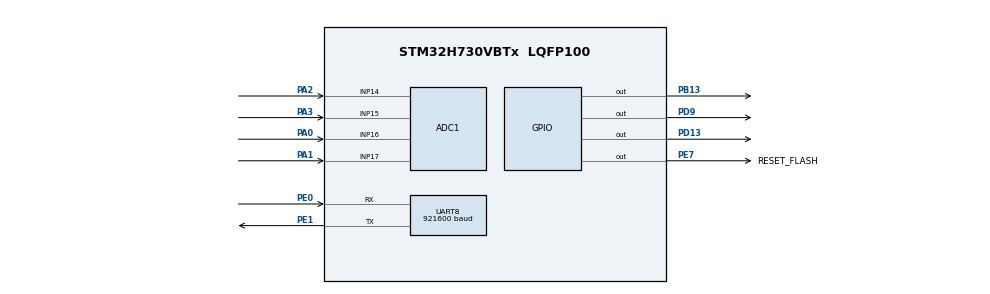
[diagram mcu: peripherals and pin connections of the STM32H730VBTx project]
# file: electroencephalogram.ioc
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ADC1.Channel-6\#ChannelRegularConversion=ADC_CHANNEL_14
ADC1.Channel-7\#ChannelRegularConversion=ADC_CHANNEL_15
ADC1.Channel-8\#ChannelRegularConversion=ADC_CHANNEL_16
ADC1.Channel-9\#ChannelRegularConversion=ADC_CHANNEL_17
ADC1.ClockPrescaler=ADC_CLOCK_ASYNC_DIV1
ADC1.ContinuousConvMode=ENABLE
ADC1.ConversionDataManagement=ADC_CONVERSIONDATA_DMA_CIRCULAR
ADC1.ExternalTrigConv=ADC_SOFTWARE_START
ADC1.NbrOfConversion=4
ADC1.NbrOfConversionFlag=1
ADC1.OffsetNumber-6\#ChannelRegularConversion=ADC_OFFSET_NONE
ADC1.OffsetNumber-7\#ChannelRegularConversion=ADC_OFFSET_NONE
ADC1.OffsetNumber-8\#ChannelRegularConversion=ADC_OFFSET_NONE
ADC1.OffsetNumber-9\#ChannelRegularConversion=ADC_OFFSET_NONE
ADC1.OffsetSignedSaturation-6\#ChannelRegularConversion=DISABLE
ADC1.OffsetSignedSaturation-7\#ChannelRegularConversion=DISABLE
ADC1.OffsetSignedSaturation-8\#ChannelRegularConversion=DISABLE
ADC1.OffsetSignedSaturation-9\#ChannelRegularConversion=DISABLE
ADC1.OversamplingMode=DISABLE
ADC1.Rank-6\#ChannelRegularConversion=1
ADC1.Rank-7\#ChannelRegularConversion=2
ADC1.Rank-8\#ChannelRegularConversion=3
ADC1.Rank-9\#ChannelRegularConversion=4
ADC1.Ratio=64
ADC1.SamplingTime-6\#ChannelRegularConversion=ADC_SAMPLETIME_2CYCLES_5
ADC1.SamplingTime-7\#ChannelRegularConversion=ADC_SAMPLETIME_2CYCLES_5
ADC1.SamplingTime-8\#ChannelRegularConversion=ADC_SAMPLETIME_2CYCLES_5
ADC1.SamplingTime-9\#ChannelRegularConversion=ADC_SAMPLETIME_2CYCLES_5
ADC1.master=1
CORTEX_M7.default_mode_Activation=1
Dma.ADC1.0.Direction=DMA_PERIPH_TO_MEMORY
Dma.ADC1.0.EventEnable=DISABLE
Dma.ADC1.0.FIFOMode=DMA_FIFOMODE_DISABLE
Dma.ADC1.0.Instance=DMA1_Stream0
Dma.ADC1.0.MemDataAlignment=DMA_MDATAALIGN_HALFWORD
Dma.ADC1.0.MemInc=DMA_MINC_ENABLE
Dma.ADC1.0.Mode=DMA_CIRCULAR
Dma.ADC1.0.PeriphDataAlignment=DMA_PDATAALIGN_HALFWORD
Dma.ADC1.0.PeriphInc=DMA_PINC_DISABLE
Dma.ADC1.0.Polarity=HAL_DMAMUX_REQ_GEN_RISING
Dma.ADC1.0.Priority=DMA_PRIORITY_LOW
Dma.ADC1.0.RequestNumber=1
Dma.ADC1.0.SignalID=NONE
Dma.ADC1.0.SyncEnable=DISABLE
Dma.ADC1.0.SyncPolarity=HAL_DMAMUX_SYNC_NO_EVENT
Dma.ADC1.0.SyncRequestNumber=1
Dma.ADC1.0.SyncSignalID=NONE
Dma.Request0=ADC1
Dma.Request1=UART8_TX
Dma.UART8_TX.1.Direction=DMA_MEMORY_TO_PERIPH
Dma.UART8_TX.1.EventEnable=DISABLE
Dma.UART8_TX.1.FIFOMode=DMA_FIFOMODE_DISABLE
Dma.UART8_TX.1.Instance=DMA1_Stream1
Dma.UART8_TX.1.MemDataAlignment=DMA_MDATAALIGN_BYTE
Dma.UART8_TX.1.MemInc=DMA_MINC_ENABLE
Dma.UART8_TX.1.Mode=DMA_CIRCULAR
Dma.UART8_TX.1.PeriphDataAlignment=DMA_PDATAALIGN_BYTE
Dma.UART8_TX.1.PeriphInc=DMA_PINC_DISABLE
Dma.UART8_TX.1.Polarity=HAL_DMAMUX_REQ_GEN_RISING
Dma.UART8_TX.1.Priority=DMA_PRIORITY_LOW
Dma.UART8_TX.1.RequestNumber=1
Dma.UART8_TX.1.SignalID=NONE
Dma.UART8_TX.1.SyncEnable=DISABLE
Dma.UART8_TX.1.SyncPolarity=HAL_DMAMUX_SYNC_NO_EVENT
Dma.UART8_TX.1.SyncRequestNumber=1
Dma.UART8_TX.1.SyncSignalID=NONE
Mcu.Family=STM32H7
Mcu.Name=STM32H730VBTx
Mcu.Package=LQFP100
NVIC.DMA1_Stream0_IRQn=true\:0\:0\:false\:false\:true\:false\:true\:true
NVIC.DMA1_Stream1_IRQn=true\:0\:0\:false\:false\:true\:false\:true\:true
NVIC.PriorityGroup=NVIC_PRIORITYGROUP_4
NVIC.UART8_IRQn=true\:3\:0\:true\:false\:true\:true\:true\:true
PA0.Mode=IN16-Single-Ended
PA0.Signal=ADC1_INP16
PA1.Mode=IN17-Single-Ended
PA1.Signal=ADC1_INP17
PA13(JTMS/SWDIO).Mode=Trace_Asynchronous_SW
PA13(JTMS/SWDIO).Signal=DEBUG_JTMS-SWDIO
PA14(JTCK/SWCLK).Mode=Trace_Asynchronous_SW
PA14(JTCK/SWCLK).Signal=DEBUG_JTCK-SWCLK
PA2.Signal=ADCx_INP14
PA3.Signal=ADCx_INP15
PA6.Signal=OCTOSPIM_P1_IO3
PA7.Signal=OCTOSPIM_P1_IO2
PB1.Signal=OCTOSPIM_P1_IO0
PB13.Signal=GPIO_Output
PB2.Signal=OCTOSPIM_P1_CLK
PB3(JTDO/TRACESWO).Mode=Trace_Asynchronous_SW
PB3(JTDO/TRACESWO).Signal=DEBUG_JTDO-SWO
PD13.Signal=GPIO_Output
PD9.Signal=GPIO_Output
PE0.Mode=Asynchronous
PE0.Signal=UART8_RX
PE1.Mode=Asynchronous
PE1.Signal=UART8_TX
PE7.GPIO_Label=RESET_FLASH
PE7.Signal=GPIO_Output
PH0-OSC_IN.Mode=HSE-External-Oscillator
PH0-OSC_IN.Signal=RCC_OSC_IN
PH1-OSC_OUT.Mode=HSE-External-Oscillator
PH1-OSC_OUT.Signal=RCC_OSC_OUT
ProjectManager.HeapSize=0x200
ProjectManager.StackSize=0x400
ProjectManager.TargetToolchain=STM32CubeIDE
RCC.ADCFreq_Value=38400000
RCC.APB1Freq_Value=30000000
RCC.APB2Freq_Value=30000000
RCC.APB3Freq_Value=30000000
RCC.APB4Freq_Value=30000000
RCC.CortexFreq_Value=30000000
RCC.DIVM1=2
RCC.DIVM2=4
RCC.DIVN1=16
RCC.DIVN2=12
RCC.DIVP2=5
RCC.DIVQ1=5
RCC.HCLKFreq_Value=30000000
RCC.HSE_VALUE=30000000
RCC.PLL2FRACN=0
RCC.PLL2_VCO_SEL-AdvancedSettings=RCC_PLL2VCOWIDE
RCC.PLLFRACN=0
RCC.SYSCLKFreq_VALUE=30000000
RCC.SYSCLKSource=RCC_SYSCLKSOURCE_HSE
RCC.USBFreq_Value=102400000
SH.ADCx_INP14.0=ADC1_INP14,IN14-Single-Ended
SH.ADCx_INP15.0=ADC1_INP15,IN15-Single-Ended
TIM3.Period=250-1
TIM3.Prescaler=30-1
TIM3.TIM_MasterOutputTrigger=TIM_TRGO_UPDATE
UART8.BaudRate=921600
VP_MEMORYMAP_VS_MEMORYMAP.Mode=CurAppReg
VP_TIM3_VS_ClockSourceINT.Mode=Internal
board=custom

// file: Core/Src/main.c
/* USER CODE BEGIN Header */
/**
  ******************************************************************************
  * @file           : main.c
  * @brief          : Main program body
  ******************************************************************************
  * @attention
  *
  * Copyright (c) 2025 STMicroelectronics.
  * All rights reserved.
  *
  * This software is licensed under terms that can be found in the LICENSE file
  * in the root directory of this software component.
  * If no LICENSE file comes with this software, it is provided AS-IS.
  *
  ******************************************************************************
  */
/* USER CODE END Header */
#include "main.h"

/* USER CODE BEGIN Includes */
#include "main.h"
#include "app.h"

/* USER CODE END Includes */

ADC_HandleTypeDef hadc1;
DMA_HandleTypeDef hdma_adc1;

TIM_HandleTypeDef htim3;

void SystemClock_Config(void);
static void MPU_Config(void);
static void MX_GPIO_Init(void);
static void MX_DMA_Init(void);
static void MX_UART8_Init(void);
static void MX_ADC1_Init(void);
static void MX_TIM3_Init(void);

int main(void)
{

  /* MPU Configuration--------------------------------------------------------*/
  MPU_Config();

  /* MCU Configuration--------------------------------------------------------*/

  /* Reset of all peripherals, Initializes the Flash interface and the Systick. */
  HAL_Init();

  /* Configure the system clock */
  SystemClock_Config();

  /* Initialize all configured peripherals */
  MX_GPIO_Init();
  MX_DMA_Init();
  MX_UART8_Init();
  MX_ADC1_Init();
  MX_TIM3_Init();
  /* USER CODE BEGIN 2 */

  app_setup();

  /* USER CODE END 2 */

  /* Infinite loop */
  while (1)
  {

    /* USER CODE BEGIN 3 */
	  app_loop();
  }
  /* USER CODE END 3 */
}

void SystemClock_Config(void)
{
  RCC_OscInitTypeDef RCC_OscInitStruct = {0};
  RCC_ClkInitTypeDef RCC_ClkInitStruct = {0};

  /** Supply configuration update enable
  */
  HAL_PWREx_ConfigSupply(PWR_LDO_SUPPLY);

  /** Configure the main internal regulator output voltage
  */
  __HAL_PWR_VOLTAGESCALING_CONFIG(PWR_REGULATOR_VOLTAGE_SCALE3);

  while(!__HAL_PWR_GET_FLAG(PWR_FLAG_VOSRDY)) {}

  /** Macro to configure the PLL clock source
  */
  __HAL_RCC_PLL_PLLSOURCE_CONFIG(RCC_PLLSOURCE_HSI);

  /** Initializes the RCC Oscillators according to the specified parameters
  * in the RCC_OscInitTypeDef structure.
  */
  RCC_OscInitStruct.OscillatorType = RCC_OSCILLATORTYPE_HSI|RCC_OSCILLATORTYPE_HSE;
  RCC_OscInitStruct.HSEState = RCC_HSE_ON;
  RCC_OscInitStruct.HSIState = RCC_HSI_DIV1;
  RCC_OscInitStruct.HSICalibrationValue = 64;
  RCC_OscInitStruct.PLL.PLLState = RCC_PLL_NONE;
  if (HAL_RCC_OscConfig(&RCC_OscInitStruct) != HAL_OK)
  {
    Error_Handler();
  }

  /** Initializes the CPU, AHB and APB buses clocks
  */
  RCC_ClkInitStruct.ClockType = RCC_CLOCKTYPE_HCLK|RCC_CLOCKTYPE_SYSCLK
                              |RCC_CLOCKTYPE_PCLK1|RCC_CLOCKTYPE_PCLK2
                              |RCC_CLOCKTYPE_D3PCLK1|RCC_CLOCKTYPE_D1PCLK1;
  RCC_ClkInitStruct.SYSCLKSource = RCC_SYSCLKSOURCE_HSE;
  RCC_ClkInitStruct.SYSCLKDivider = RCC_SYSCLK_DIV1;
  RCC_ClkInitStruct.AHBCLKDivider = RCC_HCLK_DIV1;
  RCC_ClkInitStruct.APB3CLKDivider = RCC_APB3_DIV1;
  RCC_ClkInitStruct.APB1CLKDivider = RCC_APB1_DIV1;
  RCC_ClkInitStruct.APB2CLKDivider = RCC_APB2_DIV1;
  RCC_ClkInitStruct.APB4CLKDivider = RCC_APB4_DIV1;

  if (HAL_RCC_ClockConfig(&RCC_ClkInitStruct, FLASH_LATENCY_0) != HAL_OK)
  {
    Error_Handler();
  }
}

static void MX_ADC1_Init(void)
{

  ADC_MultiModeTypeDef multimode = {0};
  ADC_ChannelConfTypeDef sConfig = {0};

  /** Common config
  */
  hadc1.Instance = ADC1;
  hadc1.Init.ClockPrescaler = ADC_CLOCK_ASYNC_DIV1;
  hadc1.Init.Resolution = ADC_RESOLUTION_16B;
  hadc1.Init.ScanConvMode = ADC_SCAN_ENABLE;
  hadc1.Init.EOCSelection = ADC_EOC_SINGLE_CONV;
  hadc1.Init.LowPowerAutoWait = DISABLE;
  hadc1.Init.ContinuousConvMode = ENABLE;
  hadc1.Init.NbrOfConversion = 4;
  hadc1.Init.DiscontinuousConvMode = DISABLE;
  hadc1.Init.ExternalTrigConv = ADC_SOFTWARE_START;
  hadc1.Init.ExternalTrigConvEdge = ADC_EXTERNALTRIGCONVEDGE_NONE;
  hadc1.Init.ConversionDataManagement = ADC_CONVERSIONDATA_DMA_CIRCULAR;
  hadc1.Init.Overrun = ADC_OVR_DATA_PRESERVED;
  hadc1.Init.LeftBitShift = ADC_LEFTBITSHIFT_NONE;
  hadc1.Init.OversamplingMode = DISABLE;
  hadc1.Init.Oversampling.Ratio = 64;
  if (HAL_ADC_Init(&hadc1) != HAL_OK)
  {
    Error_Handler();
  }

  /** Configure the ADC multi-mode
  */
  multimode.Mode = ADC_MODE_INDEPENDENT;
  if (HAL_ADCEx_MultiModeConfigChannel(&hadc1, &multimode) != HAL_OK)
  {
    Error_Handler();
  }

  /** Configure Regular Channel
  */
  sConfig.Channel = ADC_CHANNEL_14;
  sConfig.Rank = ADC_REGULAR_RANK_1;
  sConfig.SamplingTime = ADC_SAMPLETIME_2CYCLES_5;
  sConfig.SingleDiff = ADC_SINGLE_ENDED;
  sConfig.OffsetNumber = ADC_OFFSET_NONE;
  sConfig.Offset = 0;
  sConfig.OffsetSignedSaturation = DISABLE;
  if (HAL_ADC_ConfigChannel(&hadc1, &sConfig) != HAL_OK)
  {
    Error_Handler();
  }

  /** Configure Regular Channel
  */
  sConfig.Channel = ADC_CHANNEL_15;
  sConfig.Rank = ADC_REGULAR_RANK_2;
  if (HAL_ADC_ConfigChannel(&hadc1, &sConfig) != HAL_OK)
  {
    Error_Handler();
  }

  /** Configure Regular Channel
  */
  sConfig.Channel = ADC_CHANNEL_16;
  sConfig.Rank = ADC_REGULAR_RANK_3;
  if (HAL_ADC_ConfigChannel(&hadc1, &sConfig) != HAL_OK)
  {
    Error_Handler();
  }

  /** Configure Regular Channel
  */
  sConfig.Channel = ADC_CHANNEL_17;
  sConfig.Rank = ADC_REGULAR_RANK_4;
  if (HAL_ADC_ConfigChannel(&hadc1, &sConfig) != HAL_OK)
  {
    Error_Handler();
  }

}

static void MX_TIM3_Init(void)
{

  TIM_ClockConfigTypeDef sClockSourceConfig = {0};
  TIM_MasterConfigTypeDef sMasterConfig = {0};

  htim3.Instance = TIM3;
  htim3.Init.Prescaler = 30-1;
  htim3.Init.CounterMode = TIM_COUNTERMODE_UP;
  htim3.Init.Period = 250-1;
  htim3.Init.ClockDivision = TIM_CLOCKDIVISION_DIV1;
  htim3.Init.AutoReloadPreload = TIM_AUTORELOAD_PRELOAD_DISABLE;
  if (HAL_TIM_Base_Init(&htim3) != HAL_OK)
  {
    Error_Handler();
  }
  sClockSourceConfig.ClockSource = TIM_CLOCKSOURCE_INTERNAL;
  if (HAL_TIM_ConfigClockSource(&htim3, &sClockSourceConfig) != HAL_OK)
  {
    Error_Handler();
  }
  sMasterConfig.MasterOutputTrigger = TIM_TRGO_UPDATE;
  sMasterConfig.MasterSlaveMode = TIM_MASTERSLAVEMODE_DISABLE;
  if (HAL_TIMEx_MasterConfigSynchronization(&htim3, &sMasterConfig) != HAL_OK)
  {
    Error_Handler();
  }

}

static void MX_UART8_Init(void)
{

  LL_USART_InitTypeDef UART_InitStruct = {0};

  LL_GPIO_InitTypeDef GPIO_InitStruct = {0};
  RCC_PeriphCLKInitTypeDef PeriphClkInitStruct = {0};

  /** Initializes the peripherals clock
  */
  PeriphClkInitStruct.PeriphClockSelection = RCC_PERIPHCLK_UART8;
  PeriphClkInitStruct.Usart234578ClockSelection = RCC_USART234578CLKSOURCE_D2PCLK1;
  if (HAL_RCCEx_PeriphCLKConfig(&PeriphClkInitStruct) != HAL_OK)
  {
    Error_Handler();
  }

  /* Peripheral clock enable */
  LL_APB1_GRP1_EnableClock(LL_APB1_GRP1_PERIPH_UART8);

  LL_AHB4_GRP1_EnableClock(LL_AHB4_GRP1_PERIPH_GPIOE);
  /**UART8 GPIO Configuration
  PE0   ------> UART8_RX
  PE1   ------> UART8_TX
  */
  GPIO_InitStruct.Pin = LL_GPIO_PIN_0|LL_GPIO_PIN_1;
  GPIO_InitStruct.Mode = LL_GPIO_MODE_ALTERNATE;
  GPIO_InitStruct.Speed = LL_GPIO_SPEED_FREQ_LOW;
  GPIO_InitStruct.OutputType = LL_GPIO_OUTPUT_PUSHPULL;
  GPIO_InitStruct.Pull = LL_GPIO_PULL_NO;
  GPIO_InitStruct.Alternate = LL_GPIO_AF_8;
  LL_GPIO_Init(GPIOE, &GPIO_InitStruct);

  /* UART8 DMA Init */

  /* UART8_TX Init */
  LL_DMA_SetPeriphRequest(DMA1, LL_DMA_STREAM_1, LL_DMAMUX1_REQ_UART8_TX);

  LL_DMA_SetDataTransferDirection(DMA1, LL_DMA_STREAM_1, LL_DMA_DIRECTION_MEMORY_TO_PERIPH);

  LL_DMA_SetStreamPriorityLevel(DMA1, LL_DMA_STREAM_1, LL_DMA_PRIORITY_LOW);

  LL_DMA_SetMode(DMA1, LL_DMA_STREAM_1, LL_DMA_MODE_CIRCULAR);

  LL_DMA_SetPeriphIncMode(DMA1, LL_DMA_STREAM_1, LL_DMA_PERIPH_NOINCREMENT);

  LL_DMA_SetMemoryIncMode(DMA1, LL_DMA_STREAM_1, LL_DMA_MEMORY_INCREMENT);

  LL_DMA_SetPeriphSize(DMA1, LL_DMA_STREAM_1, LL_DMA_PDATAALIGN_BYTE);

  LL_DMA_SetMemorySize(DMA1, LL_DMA_STREAM_1, LL_DMA_MDATAALIGN_BYTE);

  LL_DMA_DisableFifoMode(DMA1, LL_DMA_STREAM_1);

  /* UART8 interrupt Init */
  NVIC_SetPriority(UART8_IRQn, NVIC_EncodePriority(NVIC_GetPriorityGrouping(),3, 0));
  NVIC_EnableIRQ(UART8_IRQn);

  UART_InitStruct.PrescalerValue = LL_USART_PRESCALER_DIV1;
  UART_InitStruct.BaudRate = 921600;
  UART_InitStruct.DataWidth = LL_USART_DATAWIDTH_8B;
  UART_InitStruct.StopBits = LL_USART_STOPBITS_1;
  UART_InitStruct.Parity = LL_USART_PARITY_NONE;
  UART_InitStruct.TransferDirection = LL_USART_DIRECTION_TX_RX;
  UART_InitStruct.HardwareFlowControl = LL_USART_HWCONTROL_NONE;
  UART_InitStruct.OverSampling = LL_USART_OVERSAMPLING_16;
  LL_USART_Init(UART8, &UART_InitStruct);
  LL_USART_DisableFIFO(UART8);
  LL_USART_SetTXFIFOThreshold(UART8, LL_USART_FIFOTHRESHOLD_1_8);
  LL_USART_SetRXFIFOThreshold(UART8, LL_USART_FIFOTHRESHOLD_1_8);
  LL_USART_ConfigAsyncMode(UART8);

  LL_USART_Enable(UART8);

  /* Polling UART8 initialisation */
  while((!(LL_USART_IsActiveFlag_TEACK(UART8))) || (!(LL_USART_IsActiveFlag_REACK(UART8))))
  {
  }

}

static void MX_DMA_Init(void)
{

  /* DMA controller clock enable */
  __HAL_RCC_DMA1_CLK_ENABLE();

  /* DMA interrupt init */
  /* DMA1_Stream0_IRQn interrupt configuration */
  HAL_NVIC_SetPriority(DMA1_Stream0_IRQn, 0, 0);
  HAL_NVIC_EnableIRQ(DMA1_Stream0_IRQn);
  /* DMA1_Stream1_IRQn interrupt configuration */
  NVIC_SetPriority(DMA1_Stream1_IRQn, NVIC_EncodePriority(NVIC_GetPriorityGrouping(),0, 0));
  NVIC_EnableIRQ(DMA1_Stream1_IRQn);

}

static void MX_GPIO_Init(void)
{
  GPIO_InitTypeDef GPIO_InitStruct = {0};

  /* GPIO Ports Clock Enable */
  __HAL_RCC_GPIOH_CLK_ENABLE();
  __HAL_RCC_GPIOA_CLK_ENABLE();
  __HAL_RCC_GPIOB_CLK_ENABLE();
  __HAL_RCC_GPIOE_CLK_ENABLE();
  __HAL_RCC_GPIOD_CLK_ENABLE();

  /*Configure GPIO pin Output Level */
  HAL_GPIO_WritePin(RESET_FLASH_GPIO_Port, RESET_FLASH_Pin, GPIO_PIN_RESET);

  /*Configure GPIO pin Output Level */
  HAL_GPIO_WritePin(GPIOB, GPIO_PIN_13, GPIO_PIN_RESET);

  /*Configure GPIO pin Output Level */
  HAL_GPIO_WritePin(GPIOD, GPIO_PIN_9|GPIO_PIN_13, GPIO_PIN_RESET);

  /*Configure GPIO pin : PA6 */
  GPIO_InitStruct.Pin = GPIO_PIN_6;
  GPIO_InitStruct.Mode = GPIO_MODE_AF_PP;
  GPIO_InitStruct.Pull = GPIO_NOPULL;
  GPIO_InitStruct.Speed = GPIO_SPEED_FREQ_VERY_HIGH;
  GPIO_InitStruct.Alternate = GPIO_AF6_OCTOSPIM_P1;
  HAL_GPIO_Init(GPIOA, &GPIO_InitStruct);

  /*Configure GPIO pin : PA7 */
  GPIO_InitStruct.Pin = GPIO_PIN_7;
  GPIO_InitStruct.Mode = GPIO_MODE_AF_PP;
  GPIO_InitStruct.Pull = GPIO_NOPULL;
  GPIO_InitStruct.Speed = GPIO_SPEED_FREQ_VERY_HIGH;
  GPIO_InitStruct.Alternate = GPIO_AF10_OCTOSPIM_P1;
  HAL_GPIO_Init(GPIOA, &GPIO_InitStruct);

  /*Configure GPIO pin : PB1 */
  GPIO_InitStruct.Pin = GPIO_PIN_1;
  GPIO_InitStruct.Mode = GPIO_MODE_AF_PP;
  GPIO_InitStruct.Pull = GPIO_NOPULL;
  GPIO_InitStruct.Speed = GPIO_SPEED_FREQ_VERY_HIGH;
  GPIO_InitStruct.Alternate = GPIO_AF4_OCTOSPIM_P1;
  HAL_GPIO_Init(GPIOB, &GPIO_InitStruct);

  /*Configure GPIO pin : PB2 */
  GPIO_InitStruct.Pin = GPIO_PIN_2;
  GPIO_InitStruct.Mode = GPIO_MODE_AF_PP;
  GPIO_InitStruct.Pull = GPIO_NOPULL;
  GPIO_InitStruct.Speed = GPIO_SPEED_FREQ_VERY_HIGH;
  GPIO_InitStruct.Alternate = GPIO_AF9_OCTOSPIM_P1;
  HAL_GPIO_Init(GPIOB, &GPIO_InitStruct);

  /*Configure GPIO pin : RESET_FLASH_Pin */
  GPIO_InitStruct.Pin = RESET_FLASH_Pin;
  GPIO_InitStruct.Mode = GPIO_MODE_OUTPUT_PP;
  GPIO_InitStruct.Pull = GPIO_NOPULL;
  GPIO_InitStruct.Speed = GPIO_SPEED_FREQ_LOW;
  HAL_GPIO_Init(RESET_FLASH_GPIO_Port, &GPIO_InitStruct);

  /*Configure GPIO pin : PB13 */
  GPIO_InitStruct.Pin = GPIO_PIN_13;
  GPIO_InitStruct.Mode = GPIO_MODE_OUTPUT_PP;
  GPIO_InitStruct.Pull = GPIO_NOPULL;
  GPIO_InitStruct.Speed = GPIO_SPEED_FREQ_LOW;
  HAL_GPIO_Init(GPIOB, &GPIO_InitStruct);

  /*Configure GPIO pins : PD9 PD13 */
  GPIO_InitStruct.Pin = GPIO_PIN_9|GPIO_PIN_13;
  GPIO_InitStruct.Mode = GPIO_MODE_OUTPUT_PP;
  GPIO_InitStruct.Pull = GPIO_NOPULL;
  GPIO_InitStruct.Speed = GPIO_SPEED_FREQ_LOW;
  HAL_GPIO_Init(GPIOD, &GPIO_InitStruct);

}

 /* MPU Configuration */

void MPU_Config(void)
{
  MPU_Region_InitTypeDef MPU_InitStruct = {0};

  /* Disables the MPU */
  HAL_MPU_Disable();

  /** Initializes and configures the Region and the memory to be protected
  */
  MPU_InitStruct.Enable = MPU_REGION_ENABLE;
  MPU_InitStruct.Number = MPU_REGION_NUMBER0;
  MPU_InitStruct.BaseAddress = 0x0;
  MPU_InitStruct.Size = MPU_REGION_SIZE_4GB;
  MPU_InitStruct.SubRegionDisable = 0x87;
  MPU_InitStruct.TypeExtField = MPU_TEX_LEVEL0;
  MPU_InitStruct.AccessPermission = MPU_REGION_NO_ACCESS;
  MPU_InitStruct.DisableExec = MPU_INSTRUCTION_ACCESS_DISABLE;
  MPU_InitStruct.IsShareable = MPU_ACCESS_SHAREABLE;
  MPU_InitStruct.IsCacheable = MPU_ACCESS_NOT_CACHEABLE;
  MPU_InitStruct.IsBufferable = MPU_ACCESS_NOT_BUFFERABLE;

  HAL_MPU_ConfigRegion(&MPU_InitStruct);
  /* Enables the MPU */
  HAL_MPU_Enable(MPU_PRIVILEGED_DEFAULT);

}

void Error_Handler(void)
{
  __disable_irq();
  while (1)
  {
  }
}
